VERSION ""

NS_ :

BS_:

BU_:

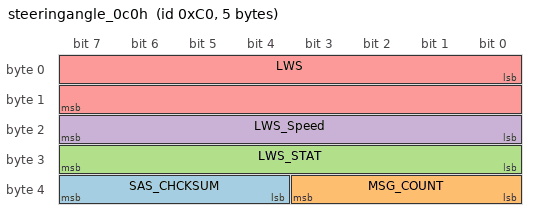
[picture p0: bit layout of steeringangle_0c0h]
BO_ 192 steeringangle_0c0h: 5 Vector__XXX
 SG_ SAS_CHCKSUM : 36|4@1+ (1,0) [0|0] "" Vector__XXX
 SG_ MSG_COUNT : 32|4@1+ (1,0) [0|0] "" Vector__XXX
 SG_ LWS_STAT : 24|8@1+ (1,0) [0|0] "" Vector__XXX
 SG_ LWS_Speed : 16|8@1+ (4,0) [0|0] "°/s" Vector__XXX
 SG_ LWS : 0|16@1- (0.1,0) [-40|40] "°" Vector__XXX

BA_DEF_  "BusType" STRING ;
BA_DEF_DEF_  "BusType" "CAN";
